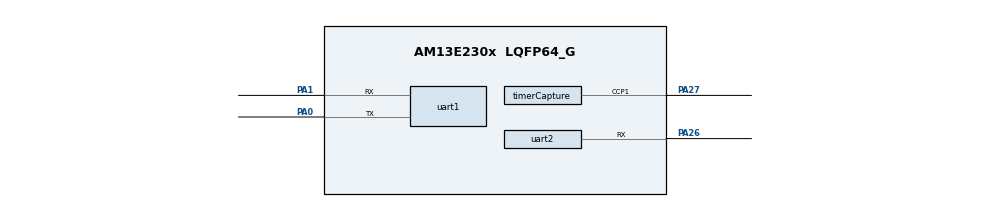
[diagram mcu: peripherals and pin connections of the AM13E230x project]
/**
 *
 * @cliArgs --device "AM13E230x" --part "AM13E230x" --package "LQFP64_G" --product "AM13E2X SDK@26.01.00"
 * @versions {"tool":"1.28.1+4785"}
 */

/**
 * Import the modules used in this configuration.
 */
const crcp          = scripting.addModule("/drivers/crcp", {}, false);
const crcp1         = crcp.addInstance();
const sysctl        = scripting.addModule("/drivers/sysctl");
const systick       = scripting.addModule("/drivers/systick");
const timerCapture  = scripting.addModule("/drivers/timerCapture", {}, false);
const timerCapture1 = timerCapture.addInstance();
const uart          = scripting.addModule("/drivers/uart", {}, false);
const uart1         = uart.addInstance();
const uart2         = uart.addInstance();

/**
 * Write custom configuration values to the imported modules.
 */
crcp1.$name   = "APP_CRC_0";
crcp1.profile = "CONFIG_PROFILE_2";

sysctl.SYSPLL_Qdiv   = 32;
sysctl.MCLKSource    = "DL_SYSCTL_MCLK_SOURCE_SYSOSC";
sysctl.SYSPLL_CLK0En = false;
sysctl.SYSPLL_CLK1En = false;

systick.periodEnable = true;
systick.period       = 16000000;

timerCapture1.$name                          = "SIG_TIMER";
timerCapture1.ccIndex                        = 1;
timerCapture1.captMode                       = "DL_TIMER_CAPTURE_MODE_PERIOD_CAPTURE_UP";
timerCapture1.captEdgeDetection              = "DL_TIMER_CAPTURE_EDGE_DETECTION_MODE_EDGE";
timerCapture1.timerPeriod                    = "26.0417 us";
timerCapture1.filterPeriod                   = "DL_TIMER_CC_INPUT_FILT_FP_PER_8";
timerCapture1.peripheral.$assign             = "TIMG4_0";
timerCapture1.peripheral.ccp1Pin.$assign     = "PA27";
timerCapture1.ccp1PinConfig.$name            = "drivers_gpio_v0_gpioPinConfig2";
timerCapture1.ccp1PinConfig.enableConfig     = true;
timerCapture1.ccp1PinConfig.internalResistor = "PULL_UP";

uart1.$name                            = "SIG_UART_UC4";
uart1.targetBaudRate                   = 38400;
uart1.peripheral.$assign               = "UC4";
uart1.peripheral.rxPin.$assign         = "PA1";
uart1.peripheral.txPin.$assign         = "PA0";
uart1.txPinConfig.direction            = scripting.forceWrite("OUTPUT");
uart1.txPinConfig.hideOutputInversion  = scripting.forceWrite(false);
uart1.txPinConfig.onlyInternalResistor = scripting.forceWrite(false);
uart1.txPinConfig.passedPeripheralType = scripting.forceWrite("Digital");
uart1.txPinConfig.$name                = "drivers_gpio_v0_gpioPinConfig0";
uart1.rxPinConfig.hideOutputInversion  = scripting.forceWrite(false);
uart1.rxPinConfig.onlyInternalResistor = scripting.forceWrite(false);
uart1.rxPinConfig.passedPeripheralType = scripting.forceWrite("Digital");
uart1.rxPinConfig.$name                = "drivers_gpio_v0_gpioPinConfig1";

uart2.$name                            = "SIG_UART_PA26";
uart2.direction                        = "DL_UART_DIRECTION_RX";
uart2.targetBaudRate                   = 38400;
uart2.rxPinConfig.hideOutputInversion  = scripting.forceWrite(false);
uart2.rxPinConfig.onlyInternalResistor = scripting.forceWrite(false);
uart2.rxPinConfig.passedPeripheralType = scripting.forceWrite("Digital");
uart2.rxPinConfig.$name                = "drivers_gpio_v0_gpioPinConfig3";
uart2.rxPinConfig.enableConfig         = true;
uart2.rxPinConfig.internalResistor     = "PULL_UP";
uart2.peripheral.$assign               = "UC0";
uart2.peripheral.rxPin.$assign         = "PA26";

/**
 * Pinmux solution for unlocked pins/peripherals. This ensures that minor changes to the automatic solver in a future
 * version of the tool will not impact the pinmux you originally saw.  These lines can be completely deleted in order to
 * re-solve from scratch.
 */
sysctl.peripheral.$suggestSolution = "SYSCTL";
